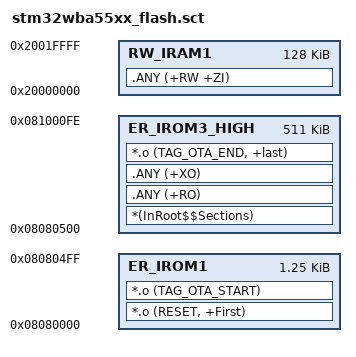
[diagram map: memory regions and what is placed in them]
; *************************************************************
; *** Scatter-Loading Description File generated by uVision ***
; *************************************************************

LR_IROM1 0x08080000 0x500 {    ; load region size_region
  ER_IROM1 0x08080000 0x500 {  ; load address = execution address
   *.o (RESET, +First)
   *.o (TAG_OTA_START)	
  }

  RW_IRAM1 0x20000000 0x00020000  {  ; RW data
   .ANY (+RW +ZI)
  }
}

LR_IROM3 0x08080500 0x7FBFF {
  ER_IROM3_HIGH 0x08080500 0x7FBFF {  ; load address = execution address	
	*(InRoot$$Sections)
	.ANY (+RO)
	.ANY (+XO)
	*.o (TAG_OTA_END, +last)	
  }
}
